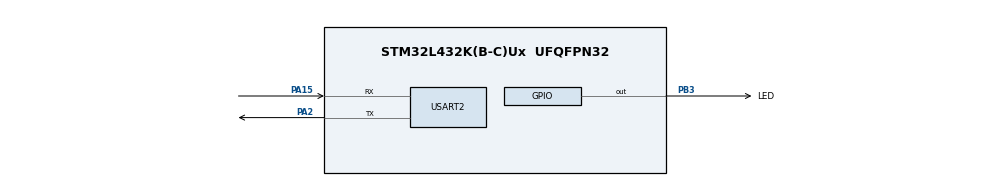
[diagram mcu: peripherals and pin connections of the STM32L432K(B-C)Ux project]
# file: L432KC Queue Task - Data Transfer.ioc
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FREERTOS.Queues01=DataTransferQueue,10,uint32_t,0,Dynamic,NULL,NULL
FREERTOS.Tasks01=defaultTask,24,128,StartDefaultTask,Default,NULL,Dynamic,NULL,NULL;SendTask,8,128,StartSendTask,Default,NULL,Dynamic,NULL,NULL;ReceiveTask,8,128,StartReceiveTask,Default,NULL,Dynamic,NULL,NULL
FREERTOS.configUSE_NEWLIB_REENTRANT=1
Mcu.Family=STM32L4
Mcu.Name=STM32L432K(B-C)Ux
Mcu.Package=UFQFPN32
NVIC.PriorityGroup=NVIC_PRIORITYGROUP_4
NVIC.TIM6_DAC_IRQn=true\:15\:0\:false\:false\:true\:false\:false\:true\:true
NVIC.TimeBase=TIM6_DAC_IRQn
NVIC.TimeBaseIP=TIM6
PA13\ (JTMS-SWDIO).Mode=Serial_Wire
PA13\ (JTMS-SWDIO).Signal=SYS_JTMS-SWDIO
PA14\ (JTCK-SWCLK).Mode=Serial_Wire
PA14\ (JTCK-SWCLK).Signal=SYS_JTCK-SWCLK
PA15\ (JTDI).Mode=Asynchronous
PA15\ (JTDI).Signal=USART2_RX
PA2.Mode=Asynchronous
PA2.Signal=USART2_TX
PB3\ (JTDO-TRACESWO).GPIO_Label=LED
PB3\ (JTDO-TRACESWO).Signal=GPIO_Output
ProjectManager.HeapSize=0x200
ProjectManager.StackSize=0x400
ProjectManager.TargetToolchain=STM32CubeIDE
RCC.HSE_VALUE=8000000
RCC.HSI48_VALUE=48000000
RCC.HSI_VALUE=16000000
RCC.LSE_VALUE=32768
RCC.MSI_VALUE=4000000
RCC.VCOOutputFreq_Value=32000000
USART2.VirtualMode-Asynchronous=VM_ASYNC
VP_FREERTOS_VS_CMSIS_V2.Mode=CMSIS_V2
VP_SYS_VS_tim6.Mode=TIM6
board=custom

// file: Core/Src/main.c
/* USER CODE BEGIN Header */
/**
  ******************************************************************************
  * @file           : main.c
  * @brief          : Main program body
  ******************************************************************************
  * @attention
  *
  * Copyright (c) 2026 STMicroelectronics.
  * All rights reserved.
  *
  * This software is licensed under terms that can be found in the LICENSE file
  * in the root directory of this software component.
  * If no LICENSE file comes with this software, it is provided AS-IS.
  *
  ******************************************************************************
  */
/* USER CODE END Header */
#include "main.h"
#include "cmsis_os.h"

/* USER CODE BEGIN Includes */

#include <stdio.h>
#include <string.h>

/* USER CODE END Includes */

UART_HandleTypeDef huart2;

/* Definitions for defaultTask */
osThreadId_t defaultTaskHandle;
const osThreadAttr_t defaultTask_attributes = {
  .name = "defaultTask",
  .stack_size = 128 * 4,
  .priority = (osPriority_t) osPriorityNormal,
};
/* Definitions for SendTask */
osThreadId_t SendTaskHandle;
const osThreadAttr_t SendTask_attributes = {
  .name = "SendTask",
  .stack_size = 128 * 4,
  .priority = (osPriority_t) osPriorityLow,
};
/* Definitions for ReceiveTask */
osThreadId_t ReceiveTaskHandle;
const osThreadAttr_t ReceiveTask_attributes = {
  .name = "ReceiveTask",
  .stack_size = 128 * 4,
  .priority = (osPriority_t) osPriorityLow,
};
/* Definitions for DataTransferQueue */
osMessageQueueId_t DataTransferQueueHandle;
const osMessageQueueAttr_t DataTransferQueue_attributes = {
  .name = "DataTransferQueue"
};

void SystemClock_Config(void);
static void MX_GPIO_Init(void);
static void MX_USART2_UART_Init(void);
void StartDefaultTask(void *argument);
void StartSendTask(void *argument);
void StartReceiveTask(void *argument);

int main(void)
{

  /* USER CODE BEGIN 1*/

  static uint8_t serial_string[51] = "";

  /* USER CODE END 1*/

  /* MCU Configuration--------------------------------------------------------*/

  /* Reset of all peripherals, Initializes the Flash interface and the Systick. */
  HAL_Init();

  /* Configure the system clock */
  SystemClock_Config();

  /* Initialize all configured peripherals */
  MX_GPIO_Init();
  MX_USART2_UART_Init();

  /* USER CODE BEGIN 2*/

  sprintf((char *)serial_string, "Hello from STM32L4 via UART.\r\n");

  /* USER CODE END 2*/

  /* Init scheduler */
  osKernelInitialize();

  /* Create the queue(s) */
  /* creation of DataTransferQueue */
  DataTransferQueueHandle = osMessageQueueNew (10, sizeof(uint32_t), &DataTransferQueue_attributes);

  /* Create the thread(s) */
  /* creation of defaultTask */
  defaultTaskHandle = osThreadNew(StartDefaultTask, NULL, &defaultTask_attributes);

  /* creation of SendTask */
  SendTaskHandle = osThreadNew(StartSendTask, NULL, &SendTask_attributes);

  /* creation of ReceiveTask */
  ReceiveTaskHandle = osThreadNew(StartReceiveTask, NULL, &ReceiveTask_attributes);

  /* Start scheduler */
  osKernelStart();

  /* We should never get here as control is now taken by the scheduler */

  /* Infinite loop */
  while (1)
  {

  }
}

void SystemClock_Config(void)
{
  RCC_OscInitTypeDef RCC_OscInitStruct = {0};
  RCC_ClkInitTypeDef RCC_ClkInitStruct = {0};

  /** Configure the main internal regulator output voltage
  */
  if (HAL_PWREx_ControlVoltageScaling(PWR_REGULATOR_VOLTAGE_SCALE1) != HAL_OK)
  {
    Error_Handler();
  }

  /** Initializes the RCC Oscillators according to the specified parameters
  * in the RCC_OscInitTypeDef structure.
  */
  RCC_OscInitStruct.OscillatorType = RCC_OSCILLATORTYPE_MSI;
  RCC_OscInitStruct.MSIState = RCC_MSI_ON;
  RCC_OscInitStruct.MSICalibrationValue = 0;
  RCC_OscInitStruct.MSIClockRange = RCC_MSIRANGE_6;
  RCC_OscInitStruct.PLL.PLLState = RCC_PLL_NONE;
  if (HAL_RCC_OscConfig(&RCC_OscInitStruct) != HAL_OK)
  {
    Error_Handler();
  }

  /** Initializes the CPU, AHB and APB buses clocks
  */
  RCC_ClkInitStruct.ClockType = RCC_CLOCKTYPE_HCLK|RCC_CLOCKTYPE_SYSCLK
                              |RCC_CLOCKTYPE_PCLK1|RCC_CLOCKTYPE_PCLK2;
  RCC_ClkInitStruct.SYSCLKSource = RCC_SYSCLKSOURCE_MSI;
  RCC_ClkInitStruct.AHBCLKDivider = RCC_SYSCLK_DIV1;
  RCC_ClkInitStruct.APB1CLKDivider = RCC_HCLK_DIV1;
  RCC_ClkInitStruct.APB2CLKDivider = RCC_HCLK_DIV1;

  if (HAL_RCC_ClockConfig(&RCC_ClkInitStruct, FLASH_LATENCY_0) != HAL_OK)
  {
    Error_Handler();
  }
}

static void MX_USART2_UART_Init(void)
{

  huart2.Instance = USART2;
  huart2.Init.BaudRate = 115200;
  huart2.Init.WordLength = UART_WORDLENGTH_8B;
  huart2.Init.StopBits = UART_STOPBITS_1;
  huart2.Init.Parity = UART_PARITY_NONE;
  huart2.Init.Mode = UART_MODE_TX_RX;
  huart2.Init.HwFlowCtl = UART_HWCONTROL_NONE;
  huart2.Init.OverSampling = UART_OVERSAMPLING_16;
  huart2.Init.OneBitSampling = UART_ONE_BIT_SAMPLE_DISABLE;
  huart2.AdvancedInit.AdvFeatureInit = UART_ADVFEATURE_NO_INIT;
  if (HAL_UART_Init(&huart2) != HAL_OK)
  {
    Error_Handler();
  }

}

static void MX_GPIO_Init(void)
{
  GPIO_InitTypeDef GPIO_InitStruct = {0};

  /* GPIO Ports Clock Enable */
  __HAL_RCC_GPIOA_CLK_ENABLE();
  __HAL_RCC_GPIOB_CLK_ENABLE();

  /*Configure GPIO pin Output Level */
  HAL_GPIO_WritePin(LED_GPIO_Port, LED_Pin, GPIO_PIN_RESET);

  /*Configure GPIO pin : LED_Pin */
  GPIO_InitStruct.Pin = LED_Pin;
  GPIO_InitStruct.Mode = GPIO_MODE_OUTPUT_PP;
  GPIO_InitStruct.Pull = GPIO_NOPULL;
  GPIO_InitStruct.Speed = GPIO_SPEED_FREQ_LOW;
  HAL_GPIO_Init(LED_GPIO_Port, &GPIO_InitStruct);

}

void StartDefaultTask(void *argument)
{
  for(;;)
  {
    osDelay(1);
  }
}

void StartSendTask(void *argument)
{
  /* USER CODE BEGIN StartSendTask */

  uint32_t iteration = 0;

  /* Infinite loop */
  for(;;)
  {
	iteration++;

	osMessageQueuePut(DataTransferQueueHandle,
			&iteration,
			0,
			osWaitForever);

    osDelay(2000);
  }
  /* USER CODE END StartSendTask */
}

void StartReceiveTask(void *argument)
{
  /* USER CODE BEGIN StartReceiveTask */

  uint32_t receivedIteration;
  char message[50];

  /* Infinite loop */
  for(;;)
  {

	if(osMessageQueueGet(DataTransferQueueHandle,
			&receivedIteration,
			NULL,
			osWaitForever) == osOK)

	{
	    sprintf(message,
		        "Received iteration: %lu\r\n",
		        receivedIteration);

		HAL_UART_Transmit(&huart2,
		                  (uint8_t *)message,
		                  strlen(message),
		                  HAL_MAX_DELAY);
	}
  }
  /* USER CODE END StartReceiveTask */
}

void HAL_TIM_PeriodElapsedCallback(TIM_HandleTypeDef *htim)
{
  if (htim->Instance == TIM6)
  {
    HAL_IncTick();
  }
}

void Error_Handler(void)
{
  __disable_irq();
  while (1)
  {
  }
}
